AUTOSAR XML (schema 314)
package /ComponentType
  internal behavior Sa_CDDInterface6_InternalBehavior: component=Sa_CDDInterface6
    timing event CDDInterface6_Init1_InitEvent: start-on-event=CDDInterface6_Init1, period=0
    timing event TMT_CDDInterface6_Per1: start-on-event=CDDInterface6_Per1, period=0.01
    port-api-options:
      enable-take-address=false, indirect-api=false, port=AVASelected
      enable-take-address=false, indirect-api=false, port=CAVHCSelected
      enable-take-address=false, indirect-api=false, port=CDDPorts
      enable-take-address=false, indirect-api=false, port=CityParkSelected
      enable-take-address=false, indirect-api=false, port=DampingSrlComSvcDft
      enable-take-address=false, indirect-api=false, port=DftAsstTbl
      enable-take-address=false, indirect-api=false, port=DrivingDynSrlComSvcDft
      enable-take-address=false, indirect-api=false, port=DwnldAsstGain
      enable-take-address=false, indirect-api=false, port=EnergyModeState
      enable-take-address=false, indirect-api=false, port=EngONSrlComSvcDft
      enable-take-address=false, indirect-api=false, port=EOTImpactSrlComSvcDft
      enable-take-address=false, indirect-api=false, port=EOTThermalSrlComSvcDft
      enable-take-address=false, indirect-api=false, port=FreqDepDmpSrlComSvcDft
      enable-take-address=false, indirect-api=false, port=FricLrnSrlComSvcDft
      enable-take-address=false, indirect-api=false, port=HysAddSrlComSvcDft
      enable-take-address=false, indirect-api=false, port=HystCompSrlComSvcDft
      enable-take-address=false, indirect-api=false, port=KinIntDiagSrlComSvcDft
      enable-take-address=false, indirect-api=false, port=LimitSrlComSvcDft
      enable-take-address=false, indirect-api=false, port=LoaMgrDft
      enable-take-address=false, indirect-api=false, port=LXASelected
      enable-take-address=false, indirect-api=false, port=MfgDiagInhibit
      enable-take-address=false, indirect-api=false, port=ModIdxSrlComSvcDft
      enable-take-address=false, indirect-api=false, port=MtrElecMechPolarity
      enable-take-address=false, indirect-api=false, port=MtrParmNrmLrnSrlComSvcDft
      enable-take-address=false, indirect-api=false, port=MtrVelNrmLrnSrlComSvcDft
      enable-take-address=false, indirect-api=false, port=MultIgnSrlComSvcDft
      enable-take-address=false, indirect-api=false, port=MultiModeSelected
      enable-take-address=false, indirect-api=false, port=ParkAstSrlComSvcDft
      enable-take-address=false, indirect-api=false, port=PullCompSrlComSvcDft
      enable-take-address=false, indirect-api=false, port=ReturnSrlComSvcDft
      enable-take-address=false, indirect-api=false, port=RxMsgsSrlComSvcDft
      enable-take-address=false, indirect-api=false, port=SrlComSvcDft
      enable-take-address=false, indirect-api=false, port=STTdSelected
      enable-take-address=false, indirect-api=false, port=ThermalDCSrlComSvcDft
      enable-take-address=false, indirect-api=false, port=TrqRmpSrlComSvcDft
      enable-take-address=false, indirect-api=false, port=WhlImbRejSrlComSvcDft
    runnable CDDInterface6_Init1
      data read access READ_MtrElecMechPolarity_Cnt_s08: data-element=MtrElecMechPolarity.Cnt_s08
      6 x data write access:
        WRITE_AVASelected_Cnt_lgc: data-element=AVASelected.Cnt_lgc
        WRITE_CAVHCSelected_Cnt_lgc: data-element=CAVHCSelected.Cnt_lgc
        WRITE_CityParkSelected_Cnt_lgc: data-element=CityParkSelected.Cnt_lgc
        WRITE_LXASelected_Cnt_lgc: data-element=LXASelected.Cnt_lgc
        WRITE_MultiModeSelected_Cnt_lgc: data-element=MultiModeSelected.Cnt_lgc
        WRITE_STTdSelected_Cnt_lgc: data-element=STTdSelected.Cnt_lgc
      sync call SC_CDDPorts_ApplyMtrElecMechPol: operation=CDDPorts.ApplyMtrElecMechPol, timeout=0
    runnable CDDInterface6_Per1
      data read access READ_MtrElecMechPolarity_Cnt_s08: data-element=MtrElecMechPolarity.Cnt_s08
      34 x data write access:
        WRITE_AVASelected_Cnt_lgc: data-element=AVASelected.Cnt_lgc
        WRITE_CAVHCSelected_Cnt_lgc: data-element=CAVHCSelected.Cnt_lgc
        WRITE_CityParkSelected_Cnt_lgc: data-element=CityParkSelected.Cnt_lgc
        WRITE_DampingSrlComSvcDft_Cnt_lgc: data-element=DampingSrlComSvcDft.Cnt_lgc
        WRITE_DftAsstTbl_Cnt_lgc: data-element=DftAsstTbl.Cnt_lgc
        WRITE_DrivingDynSrlComSvcDft_Cnt_lgc: data-element=DrivingDynSrlComSvcDft.Cnt_lgc
        WRITE_DwnldAsstGain_Uls_f32: data-element=DwnldAsstGain.Uls_f32
        WRITE_EnergyModeState_Cnt_enum: data-element=EnergyModeState.Cnt_enum
        WRITE_EngONSrlComSvcDft_Cnt_lgc: data-element=EngONSrlComSvcDft.Cnt_lgc
        WRITE_EOTImpactSrlComSvcDft_Cnt_lgc: data-element=EOTImpactSrlComSvcDft.Cnt_lgc
        WRITE_EOTThermalSrlComSvcDft_Cnt_lgc: data-element=EOTThermalSrlComSvcDft.Cnt_lgc
        WRITE_FreqDepDmpSrlComSvcDft_Cnt_lgc: data-element=FreqDepDmpSrlComSvcDft.Cnt_lgc
        WRITE_FricLrnSrlComSvcDft_Cnt_lgc: data-element=FricLrnSrlComSvcDft.Cnt_lgc
        WRITE_HysAddSrlComSvcDft_Cnt_lgc: data-element=HysAddSrlComSvcDft.Cnt_lgc
        WRITE_HystCompSrlComSvcDft_Cnt_lgc: data-element=HystCompSrlComSvcDft.Cnt_lgc
        WRITE_KinIntDiagSrlComSvcDft_Cnt_lgc: data-element=KinIntDiagSrlComSvcDft.Cnt_lgc
        WRITE_LimitSrlComSvcDft_Cnt_lgc: data-element=LimitSrlComSvcDft.Cnt_lgc
        WRITE_LoaMgrDft_Cnt_lgc: data-element=LoaMgrDft.Cnt_lgc
        WRITE_LXASelected_Cnt_lgc: data-element=LXASelected.Cnt_lgc
        WRITE_MfgDiagInhibit_Cnt_lgc: data-element=MfgDiagInhibit.Cnt_lgc
        WRITE_ModIdxSrlComSvcDft_Cnt_lgc: data-element=ModIdxSrlComSvcDft.Cnt_lgc
        WRITE_MtrParmNrmLrnSrlComSvcDft_Cnt_lgc: data-element=MtrParmNrmLrnSrlComSvcDft.Cnt_lgc
        WRITE_MtrVelNrmLrnSrlComSvcDft_Cnt_lgc: data-element=MtrVelNrmLrnSrlComSvcDft.Cnt_lgc
        WRITE_MultIgnSrlComSvcDft_Cnt_lgc: data-element=MultIgnSrlComSvcDft.Cnt_lgc
        WRITE_MultiModeSelected_Cnt_lgc: data-element=MultiModeSelected.Cnt_lgc
        WRITE_ParkAstSrlComSvcDft_Cnt_lgc: data-element=ParkAstSrlComSvcDft.Cnt_lgc
        WRITE_PullCompSrlComSvcDft_Cnt_lgc: data-element=PullCompSrlComSvcDft.Cnt_lgc
        WRITE_ReturnSrlComSvcDft_Cnt_lgc: data-element=ReturnSrlComSvcDft.Cnt_lgc
        WRITE_RxMsgsSrlComSvcDft_Cnt_lgc: data-element=RxMsgsSrlComSvcDft.Cnt_lgc
        WRITE_SrlComSvcDft_Cnt_b32: data-element=SrlComSvcDft.Cnt_b32
        WRITE_STTdSelected_Cnt_lgc: data-element=STTdSelected.Cnt_lgc
        WRITE_ThermalDCSrlComSvcDft_Cnt_lgc: data-element=ThermalDCSrlComSvcDft.Cnt_lgc
        WRITE_TrqRmpSrlComSvcDft_Cnt_lgc: data-element=TrqRmpSrlComSvcDft.Cnt_lgc
        WRITE_WhlImbRejSrlComSvcDft_Cnt_lgc: data-element=WhlImbRejSrlComSvcDft.Cnt_lgc
      sync call SC_CDDPorts_ApplyMtrElecMechPol: operation=CDDPorts.ApplyMtrElecMechPol, timeout=0
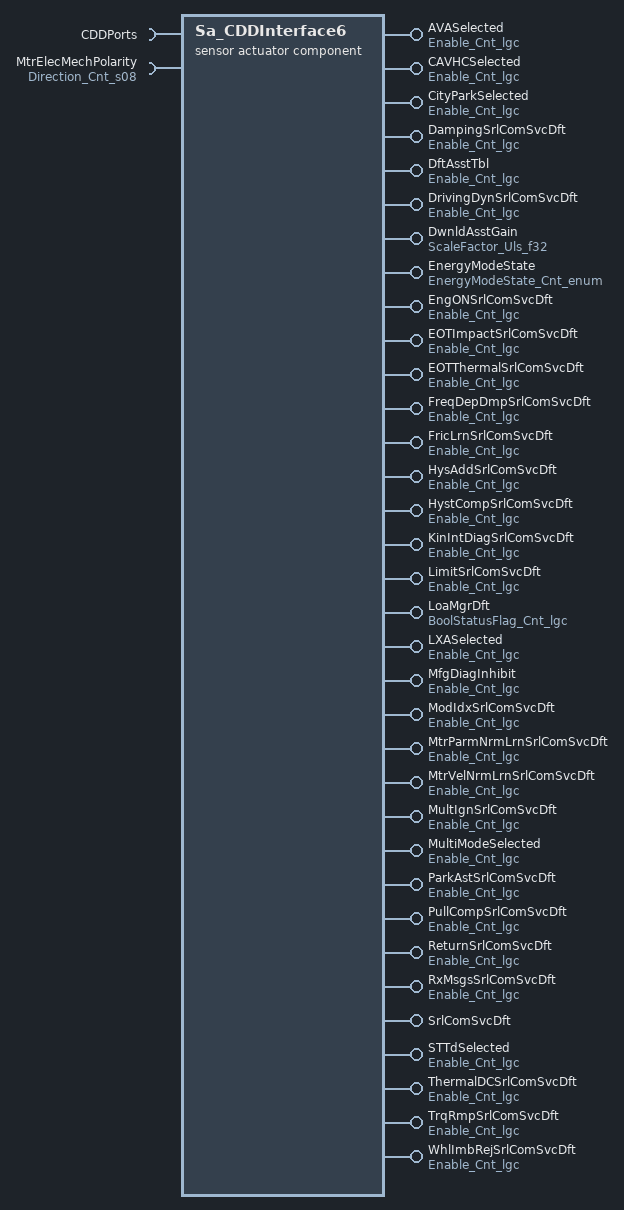
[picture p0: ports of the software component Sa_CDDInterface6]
  sensor actuator software component type Sa_CDDInterface6
    34 x provide port:
      AVASelected: unqueued-sender-com-spec{data-element=Cnt_lgc, can-invalidate=false, init-value=D_FALSE_CNT_LGC}, provided-interface=Enable_Cnt_lgc
      CAVHCSelected: unqueued-sender-com-spec{data-element=Cnt_lgc, can-invalidate=false, init-value=D_FALSE_CNT_LGC}, provided-interface=Enable_Cnt_lgc
      CityParkSelected: unqueued-sender-com-spec{data-element=Cnt_lgc, can-invalidate=false, init-value=D_FALSE_CNT_LGC}, provided-interface=Enable_Cnt_lgc
      DampingSrlComSvcDft: unqueued-sender-com-spec{data-element=Cnt_lgc, can-invalidate=false, init-value=D_FALSE_CNT_LGC}, provided-interface=Enable_Cnt_lgc
      DftAsstTbl: unqueued-sender-com-spec{data-element=Cnt_lgc, can-invalidate=false, init-value=D_FALSE_CNT_LGC}, provided-interface=Enable_Cnt_lgc
      DrivingDynSrlComSvcDft: unqueued-sender-com-spec{data-element=Cnt_lgc, can-invalidate=false, init-value=D_FALSE_CNT_LGC}, provided-interface=Enable_Cnt_lgc
      DwnldAsstGain: unqueued-sender-com-spec{data-element=Uls_f32, can-invalidate=false, init-value=D_ZERO_ULS_F32}, provided-interface=ScaleFactor_Uls_f32
      EnergyModeState: unqueued-sender-com-spec{data-element=Cnt_enum, can-invalidate=false, init-value=D_NORMALINIT_CNT_U16}, provided-interface=EnergyModeState_Cnt_enum
      EngONSrlComSvcDft: unqueued-sender-com-spec{data-element=Cnt_lgc, can-invalidate=false, init-value=D_FALSE_CNT_LGC}, provided-interface=Enable_Cnt_lgc
      EOTImpactSrlComSvcDft: unqueued-sender-com-spec{data-element=Cnt_lgc, can-invalidate=false, init-value=D_FALSE_CNT_LGC}, provided-interface=Enable_Cnt_lgc
      EOTThermalSrlComSvcDft: unqueued-sender-com-spec{data-element=Cnt_lgc, can-invalidate=false, init-value=D_FALSE_CNT_LGC}, provided-interface=Enable_Cnt_lgc
      FreqDepDmpSrlComSvcDft: unqueued-sender-com-spec{data-element=Cnt_lgc, can-invalidate=false, init-value=D_FALSE_CNT_LGC}, provided-interface=Enable_Cnt_lgc
      FricLrnSrlComSvcDft: unqueued-sender-com-spec{data-element=Cnt_lgc, can-invalidate=false, init-value=D_FALSE_CNT_LGC}, provided-interface=Enable_Cnt_lgc
      HysAddSrlComSvcDft: unqueued-sender-com-spec{data-element=Cnt_lgc, can-invalidate=false, init-value=D_FALSE_CNT_LGC}, provided-interface=Enable_Cnt_lgc
      HystCompSrlComSvcDft: unqueued-sender-com-spec{data-element=Cnt_lgc, can-invalidate=false, init-value=D_FALSE_CNT_LGC}, provided-interface=Enable_Cnt_lgc
      KinIntDiagSrlComSvcDft: unqueued-sender-com-spec{data-element=Cnt_lgc, can-invalidate=false, init-value=D_FALSE_CNT_LGC}, provided-interface=Enable_Cnt_lgc
      LimitSrlComSvcDft: unqueued-sender-com-spec{data-element=Cnt_lgc, can-invalidate=false, init-value=D_FALSE_CNT_LGC}, provided-interface=Enable_Cnt_lgc
      LoaMgrDft: unqueued-sender-com-spec{data-element=Cnt_lgc, can-invalidate=false, init-value=D_FALSE_CNT_LGC}, provided-interface=BoolStatusFlag_Cnt_lgc
      LXASelected: unqueued-sender-com-spec{data-element=Cnt_lgc, can-invalidate=false, init-value=D_FALSE_CNT_LGC}, provided-interface=Enable_Cnt_lgc
      MfgDiagInhibit: unqueued-sender-com-spec{data-element=Cnt_lgc, can-invalidate=false, init-value=D_FALSE_CNT_LGC}, provided-interface=Enable_Cnt_lgc
      ModIdxSrlComSvcDft: unqueued-sender-com-spec{data-element=Cnt_lgc, can-invalidate=false, init-value=D_FALSE_CNT_LGC}, provided-interface=Enable_Cnt_lgc
      MtrParmNrmLrnSrlComSvcDft: unqueued-sender-com-spec{data-element=Cnt_lgc, can-invalidate=false, init-value=D_FALSE_CNT_LGC}, provided-interface=Enable_Cnt_lgc
      MtrVelNrmLrnSrlComSvcDft: unqueued-sender-com-spec{data-element=Cnt_lgc, can-invalidate=false, init-value=D_FALSE_CNT_LGC}, provided-interface=Enable_Cnt_lgc
      MultIgnSrlComSvcDft: unqueued-sender-com-spec{data-element=Cnt_lgc, can-invalidate=false, init-value=D_FALSE_CNT_LGC}, provided-interface=Enable_Cnt_lgc
      MultiModeSelected: unqueued-sender-com-spec{data-element=Cnt_lgc, can-invalidate=false, init-value=D_FALSE_CNT_LGC}, provided-interface=Enable_Cnt_lgc
      ParkAstSrlComSvcDft: unqueued-sender-com-spec{data-element=Cnt_lgc, can-invalidate=false, init-value=D_FALSE_CNT_LGC}, provided-interface=Enable_Cnt_lgc
      PullCompSrlComSvcDft: unqueued-sender-com-spec{data-element=Cnt_lgc, can-invalidate=false, init-value=D_FALSE_CNT_LGC}, provided-interface=Enable_Cnt_lgc
      ReturnSrlComSvcDft: unqueued-sender-com-spec{data-element=Cnt_lgc, can-invalidate=false, init-value=D_FALSE_CNT_LGC}, provided-interface=Enable_Cnt_lgc
      RxMsgsSrlComSvcDft: unqueued-sender-com-spec{data-element=Cnt_lgc, can-invalidate=false, init-value=D_FALSE_CNT_LGC}, provided-interface=Enable_Cnt_lgc
      SrlComSvcDft: unqueued-sender-com-spec{data-element=Cnt_b32, can-invalidate=false, init-value=D_ZERO_CNT_U32}, provided-interface=SrlComSvcDft
      STTdSelected: unqueued-sender-com-spec{data-element=Cnt_lgc, can-invalidate=false, init-value=D_FALSE_CNT_LGC}, provided-interface=Enable_Cnt_lgc
      ThermalDCSrlComSvcDft: unqueued-sender-com-spec{data-element=Cnt_lgc, can-invalidate=false, init-value=D_FALSE_CNT_LGC}, provided-interface=Enable_Cnt_lgc
      TrqRmpSrlComSvcDft: unqueued-sender-com-spec{data-element=Cnt_lgc, can-invalidate=false, init-value=D_FALSE_CNT_LGC}, provided-interface=Enable_Cnt_lgc
      WhlImbRejSrlComSvcDft: unqueued-sender-com-spec{data-element=Cnt_lgc, can-invalidate=false, init-value=D_FALSE_CNT_LGC}, provided-interface=Enable_Cnt_lgc
    require port CDDPorts: required-com-specs=[ApplyMtrElecMechPol, ClearPhsReasSum], required-interface=CDDPorts
    require port MtrElecMechPolarity: unqueued-receiver-com-spec{data-element=Cnt_s08, init-value=D_ZERO_CNT_S8}, required-interface=Direction_Cnt_s08
  swc implementation Sa_CDDInterface6_Implementation: behavior=Sa_CDDInterface6_InternalBehavior
    code-descriptors:
      code Code: type=SRC
